VERSION ""

NS_ :

BS_:

BU_: Host Bootloader Application

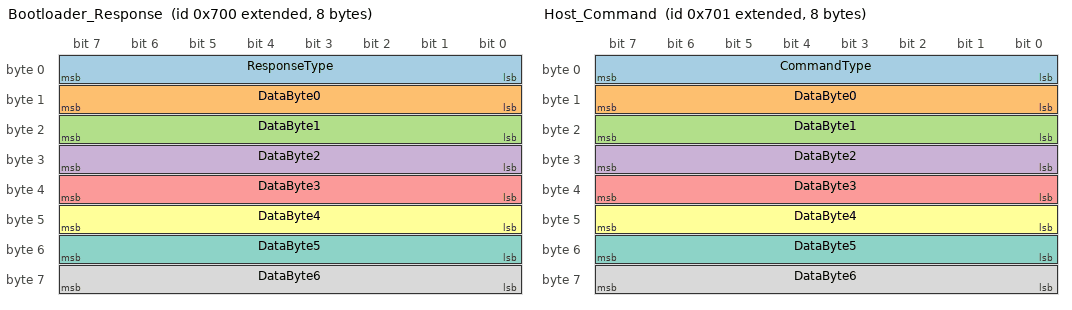
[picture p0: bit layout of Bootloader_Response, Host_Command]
BO_ 2684356352 Bootloader_Response: 8 Bootloader
 SG_ ResponseType : 0|8@1+ (1,0) [0|255] ""  Host
 SG_ DataByte0 : 8|8@1+ (1,0) [0|255] ""  Host
 SG_ DataByte1 : 16|8@1+ (1,0) [0|255] ""  Host
 SG_ DataByte2 : 24|8@1+ (1,0) [0|255] ""  Host
 SG_ DataByte3 : 32|8@1+ (1,0) [0|255] ""  Host
 SG_ DataByte4 : 40|8@1+ (1,0) [0|255] ""  Host
 SG_ DataByte5 : 48|8@1+ (1,0) [0|255] ""  Host
 SG_ DataByte6 : 56|8@1+ (1,0) [0|255] ""  Host

CM_ BO_ 2684356352 "Bootloader response messages to host PC. Contains ACK/NACK, status, data, and error information.";
CM_ SG_ 2684356352 ResponseType "Type of response: ACK(0x10), NACK(0x11), ERROR(0x12), BUSY(0x13), READY(0x14), DATA(0x15), JUMP_INFO(0x16)";
CM_ SG_ 2684356352 DataByte0 "Generic data byte 0 - ErrorCode for NACK/ERROR, Version for READY, Data for READ responses";
CM_ SG_ 2684356352 DataByte1 "Generic data byte 1 - State for STATUS, Data for READ responses";
CM_ SG_ 2684356352 DataByte2 "Generic data byte 2 - BytesWritten[0] for STATUS, Data for READ responses";
CM_ SG_ 2684356352 DataByte3 "Generic data byte 3 - BytesWritten[1] for STATUS, Data for READ responses";
CM_ SG_ 2684356352 DataByte4 "Generic data byte 4 - BytesWritten[2] for STATUS, Data for READ responses";
CM_ SG_ 2684356352 DataByte5 "Generic data byte 5 - BytesWritten[3] for STATUS, Data for READ responses";
CM_ SG_ 2684356352 DataByte6 "Generic data byte 6 - Data for READ responses";

VAL_ 2684356352 ResponseType 16 "ACK" 17 "NACK" 18 "ERROR" 19 "BUSY" 20 "READY" 21 "DATA" 22 "JUMP_INFO" ;
VAL_ 2684356352 DataByte0 0 "ERR_NONE" 1 "ERR_INVALID_COMMAND" 2 "ERR_INVALID_ADDRESS" 3 "ERR_FLASH_ERASE_FAILED" 4 "ERR_FLASH_WRITE_FAILED" 5 "ERR_INVALID_DATA_LENGTH" 6 "ERR_NO_VALID_APP" 7 "ERR_TIMEOUT" ;

BO_ 2684356353 Host_Command: 8 Host
 SG_ CommandType : 0|8@1+ (1,0) [0|255] ""  Bootloader
 SG_ DataByte0 : 8|8@1+ (1,0) [0|255] ""  Bootloader
 SG_ DataByte1 : 16|8@1+ (1,0) [0|255] ""  Bootloader
 SG_ DataByte2 : 24|8@1+ (1,0) [0|255] ""  Bootloader
 SG_ DataByte3 : 32|8@1+ (1,0) [0|255] ""  Bootloader
 SG_ DataByte4 : 40|8@1+ (1,0) [0|255] ""  Bootloader
 SG_ DataByte5 : 48|8@1+ (1,0) [0|255] ""  Bootloader
 SG_ DataByte6 : 56|8@1+ (1,0) [0|255] ""  Bootloader

CM_ BO_ 2684356353 "Host command messages to bootloader for firmware update operations";
CM_ SG_ 2684356353 CommandType "Command from host: ERASE(1), WRITE_FLASH(2), READ_FLASH(3), JUMP(4), STATUS(5), SET_ADDR(6), WRITE_DATA(7)";
CM_ SG_ 2684356353 DataByte0 "Data byte 0 - Address[31:24] for SET_ADDRESS, Data for WRITE_DATA, Length for READ_FLASH";
CM_ SG_ 2684356353 DataByte1 "Data byte 1 - Address[23:16] for SET_ADDRESS, Data for WRITE_DATA";
CM_ SG_ 2684356353 DataByte2 "Data byte 2 - Address[15:8] for SET_ADDRESS, Data for WRITE_DATA";
CM_ SG_ 2684356353 DataByte3 "Data byte 3 - Address[7:0] for SET_ADDRESS, Data for WRITE_DATA";
CM_ SG_ 2684356353 DataByte4 "Data byte 4 - DataLength for WRITE_DATA (always 0x04)";
CM_ SG_ 2684356353 DataByte5 "Data byte 5 - Reserved";
CM_ SG_ 2684356353 DataByte6 "Data byte 6 - Reserved";

VAL_ 2684356353 CommandType 1 "CMD_ERASE_FLASH" 2 "CMD_WRITE_FLASH" 3 "CMD_READ_FLASH" 4 "CMD_JUMP_TO_APP" 5 "CMD_GET_STATUS" 6 "CMD_SET_ADDRESS" 7 "CMD_WRITE_DATA" ;

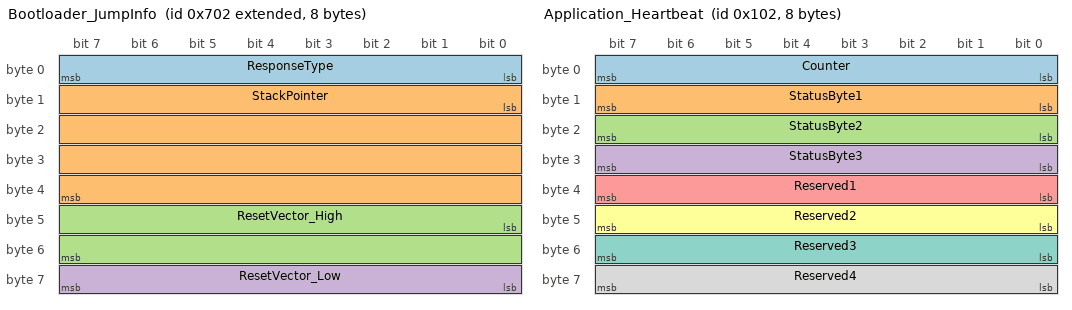
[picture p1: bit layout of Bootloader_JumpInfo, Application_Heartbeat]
BO_ 2684356354 Bootloader_JumpInfo: 8 Bootloader
 SG_ ResponseType : 0|8@1+ (1,0) [0|255] ""  Host
 SG_ StackPointer : 8|32@1+ (1,0) [0|4294967295] ""  Host
 SG_ ResetVector_High : 40|16@1+ (1,0) [0|65535] ""  Host
 SG_ ResetVector_Low : 56|8@1+ (1,0) [0|255] ""  Host

CM_ BO_ 2684356354 "Detailed jump to application diagnostics (sent immediately before jumping to application code)";
CM_ SG_ 2684356354 ResponseType "Always RESP_JUMP_INFO (0x16) for this message";
CM_ SG_ 2684356354 StackPointer "Application initial stack pointer from vector table at 0x08008000. Should be 0x2000xxxx (valid RAM address)";
CM_ SG_ 2684356354 ResetVector_High "Application reset handler address bits [23:8]. Combined with ResetVector_Low gives full address";
CM_ SG_ 2684356354 ResetVector_Low "Application reset handler address bits [7:0]. LSB should be 1 (Thumb mode). Full address should be 0x0800xxxx";

BO_ 258 Application_Heartbeat: 8 Application
 SG_ Counter : 0|8@1+ (1,0) [0|255] ""  Host,Bootloader
 SG_ StatusByte1 : 8|8@1+ (1,0) [0|255] ""  Host,Bootloader
 SG_ StatusByte2 : 16|8@1+ (1,0) [0|255] ""  Host,Bootloader
 SG_ StatusByte3 : 24|8@1+ (1,0) [0|255] ""  Host,Bootloader
 SG_ Reserved1 : 32|8@1+ (1,0) [0|255] ""  Host,Bootloader
 SG_ Reserved2 : 40|8@1+ (1,0) [0|255] ""  Host,Bootloader
 SG_ Reserved3 : 48|8@1+ (1,0) [0|255] ""  Host,Bootloader
 SG_ Reserved4 : 56|8@1+ (1,0) [0|255] ""  Host,Bootloader

CM_ BO_ 258 "Application heartbeat message sent every 10 seconds when application is running. Indicates successful jump from bootloader.";
CM_ SG_ 258 Counter "Heartbeat counter, increments with each message (rolls over at 255)";
CM_ SG_ 258 StatusByte1 "Status byte 1: Always 0x55 (signature)";
CM_ SG_ 258 StatusByte2 "Status byte 2: Always 0x01 (message type)";
CM_ SG_ 258 StatusByte3 "Status byte 3: Reserved";
CM_ SG_ 258 Reserved1 "Reserved for future use (application state, error flags, etc.)";
CM_ SG_ 258 Reserved2 "Reserved for future use";
CM_ SG_ 258 Reserved3 "Reserved for future use";
CM_ SG_ 258 Reserved4 "Reserved for future use";

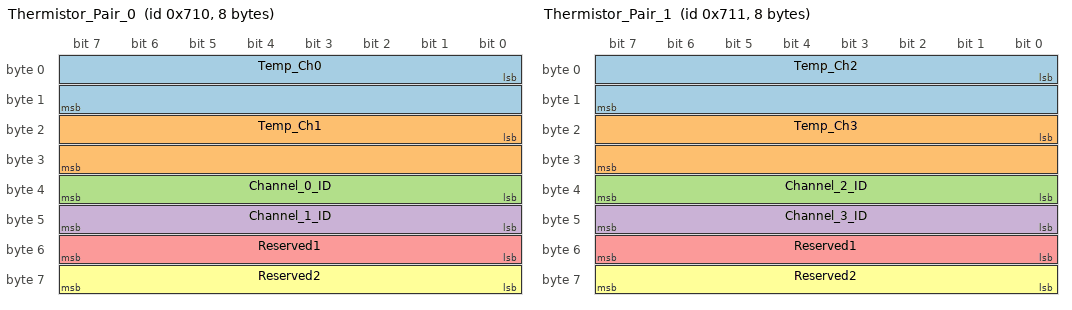
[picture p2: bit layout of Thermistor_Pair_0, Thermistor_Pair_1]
BO_ 1808 Thermistor_Pair_0: 8 Application
 SG_ Temp_Ch0 : 0|16@1- (0.1,0) [-400|1250] "degC"  Host
 SG_ Temp_Ch1 : 16|16@1- (0.1,0) [-400|1250] "degC"  Host
 SG_ Channel_0_ID : 32|8@1+ (1,0) [0|7] ""  Host
 SG_ Channel_1_ID : 40|8@1+ (1,0) [0|7] ""  Host
 SG_ Reserved1 : 48|8@1+ (1,0) [0|255] ""  Host
 SG_ Reserved2 : 56|8@1+ (1,0) [0|255] ""  Host

CM_ BO_ 1808 "Thermistor pair 0: Channels 0 and 1 temperature readings (sent every 2 seconds, 0.1°C resolution)";
CM_ SG_ 1808 Temp_Ch0 "Temperature from thermistor channel 0 (0.1°C resolution, little-endian signed 16-bit)";
CM_ SG_ 1808 Temp_Ch1 "Temperature from thermistor channel 1 (0.1°C resolution, little-endian signed 16-bit)";
CM_ SG_ 1808 Channel_0_ID "Always 0 - identifies first thermistor channel in this message";
CM_ SG_ 1808 Channel_1_ID "Always 1 - identifies second thermistor channel in this message";
CM_ SG_ 1808 Reserved1 "Reserved for future use";
CM_ SG_ 1808 Reserved2 "Reserved for future use";

BO_ 1809 Thermistor_Pair_1: 8 Application
 SG_ Temp_Ch2 : 0|16@1- (0.1,0) [-400|1250] "degC"  Host
 SG_ Temp_Ch3 : 16|16@1- (0.1,0) [-400|1250] "degC"  Host
 SG_ Channel_2_ID : 32|8@1+ (1,0) [0|7] ""  Host
 SG_ Channel_3_ID : 40|8@1+ (1,0) [0|7] ""  Host
 SG_ Reserved1 : 48|8@1+ (1,0) [0|255] ""  Host
 SG_ Reserved2 : 56|8@1+ (1,0) [0|255] ""  Host

CM_ BO_ 1809 "Thermistor pair 1: Channels 2 and 3 temperature readings (sent every 2 seconds, 0.1°C resolution)";
CM_ SG_ 1809 Temp_Ch2 "Temperature from thermistor channel 2 (0.1°C resolution, little-endian signed 16-bit)";
CM_ SG_ 1809 Temp_Ch3 "Temperature from thermistor channel 3 (0.1°C resolution, little-endian signed 16-bit)";
CM_ SG_ 1809 Channel_2_ID "Always 2 - identifies first thermistor channel in this message";
CM_ SG_ 1809 Channel_3_ID "Always 3 - identifies second thermistor channel in this message";
CM_ SG_ 1809 Reserved1 "Reserved for future use";
CM_ SG_ 1809 Reserved2 "Reserved for future use";

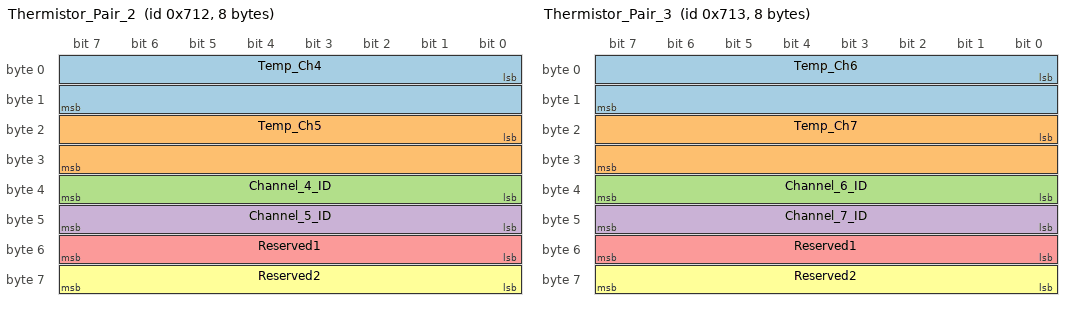
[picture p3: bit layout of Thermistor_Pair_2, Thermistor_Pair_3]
BO_ 1810 Thermistor_Pair_2: 8 Application
 SG_ Temp_Ch4 : 0|16@1- (0.1,0) [-400|1250] "degC"  Host
 SG_ Temp_Ch5 : 16|16@1- (0.1,0) [-400|1250] "degC"  Host
 SG_ Channel_4_ID : 32|8@1+ (1,0) [0|7] ""  Host
 SG_ Channel_5_ID : 40|8@1+ (1,0) [0|7] ""  Host
 SG_ Reserved1 : 48|8@1+ (1,0) [0|255] ""  Host
 SG_ Reserved2 : 56|8@1+ (1,0) [0|255] ""  Host

CM_ BO_ 1810 "Thermistor pair 2: Channels 4 and 5 temperature readings (sent every 2 seconds, 0.1°C resolution)";
CM_ SG_ 1810 Temp_Ch4 "Temperature from thermistor channel 4 (0.1°C resolution, little-endian signed 16-bit)";
CM_ SG_ 1810 Temp_Ch5 "Temperature from thermistor channel 5 (0.1°C resolution, little-endian signed 16-bit)";
CM_ SG_ 1810 Channel_4_ID "Always 4 - identifies first thermistor channel in this message";
CM_ SG_ 1810 Channel_5_ID "Always 5 - identifies second thermistor channel in this message";
CM_ SG_ 1810 Reserved1 "Reserved for future use";
CM_ SG_ 1810 Reserved2 "Reserved for future use";

BO_ 1811 Thermistor_Pair_3: 8 Application
 SG_ Temp_Ch6 : 0|16@1- (0.1,0) [-400|1250] "degC"  Host
 SG_ Temp_Ch7 : 16|16@1- (0.1,0) [-400|1250] "degC"  Host
 SG_ Channel_6_ID : 32|8@1+ (1,0) [0|7] ""  Host
 SG_ Channel_7_ID : 40|8@1+ (1,0) [0|7] ""  Host
 SG_ Reserved1 : 48|8@1+ (1,0) [0|255] ""  Host
 SG_ Reserved2 : 56|8@1+ (1,0) [0|255] ""  Host

CM_ BO_ 1811 "Thermistor pair 3: Channels 6 and 7 temperature readings (sent every 2 seconds, 0.1°C resolution)";
CM_ SG_ 1811 Temp_Ch6 "Temperature from thermistor channel 6 (0.1°C resolution, little-endian signed 16-bit)";
CM_ SG_ 1811 Temp_Ch7 "Temperature from thermistor channel 7 (0.1°C resolution, little-endian signed 16-bit)";
CM_ SG_ 1811 Channel_6_ID "Always 6 - identifies first thermistor channel in this message";
CM_ SG_ 1811 Channel_7_ID "Always 7 - identifies second thermistor channel in this message";
CM_ SG_ 1811 Reserved1 "Reserved for future use";
CM_ SG_ 1811 Reserved2 "Reserved for future use";

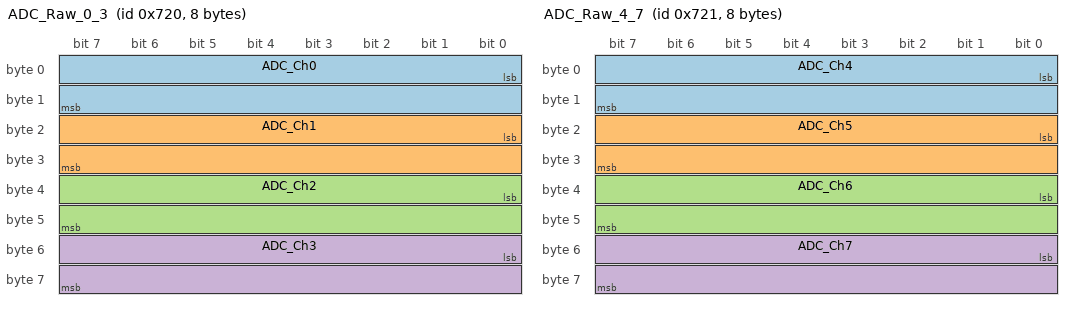
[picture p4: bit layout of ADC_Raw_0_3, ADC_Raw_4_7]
BO_ 1824 ADC_Raw_0_3: 8 Application
 SG_ ADC_Ch0 : 0|16@1+ (1,0) [0|4095] "counts"  Host
 SG_ ADC_Ch1 : 16|16@1+ (1,0) [0|4095] "counts"  Host
 SG_ ADC_Ch2 : 32|16@1+ (1,0) [0|4095] "counts"  Host
 SG_ ADC_Ch3 : 48|16@1+ (1,0) [0|4095] "counts"  Host

CM_ BO_ 1824 "Raw ADC values for thermistor channels 0-3 (diagnostic message, sent every 2 seconds)";
CM_ SG_ 1824 ADC_Ch0 "Raw 12-bit ADC reading from thermistor channel 0 (0-4095 counts)";
CM_ SG_ 1824 ADC_Ch1 "Raw 12-bit ADC reading from thermistor channel 1 (0-4095 counts)";
CM_ SG_ 1824 ADC_Ch2 "Raw 12-bit ADC reading from thermistor channel 2 (0-4095 counts)";
CM_ SG_ 1824 ADC_Ch3 "Raw 12-bit ADC reading from thermistor channel 3 (0-4095 counts)";

BO_ 1825 ADC_Raw_4_7: 8 Application
 SG_ ADC_Ch4 : 0|16@1+ (1,0) [0|4095] "counts"  Host
 SG_ ADC_Ch5 : 16|16@1+ (1,0) [0|4095] "counts"  Host
 SG_ ADC_Ch6 : 32|16@1+ (1,0) [0|4095] "counts"  Host
 SG_ ADC_Ch7 : 48|16@1+ (1,0) [0|4095] "counts"  Host

CM_ BO_ 1825 "Raw ADC values for thermistor channels 4-7 (diagnostic message, sent every 2 seconds)";
CM_ SG_ 1825 ADC_Ch4 "Raw 12-bit ADC reading from thermistor channel 4 (0-4095 counts)";
CM_ SG_ 1825 ADC_Ch5 "Raw 12-bit ADC reading from thermistor channel 5 (0-4095 counts)";
CM_ SG_ 1825 ADC_Ch6 "Raw 12-bit ADC reading from thermistor channel 6 (0-4095 counts)";
CM_ SG_ 1825 ADC_Ch7 "Raw 12-bit ADC reading from thermistor channel 7 (0-4095 counts)";

BA_DEF_ "BusType" STRING ;
BA_DEF_ BO_ "GenMsgCycleTime" INT 0 10000;
BA_DEF_ BO_ "GenMsgSendType" STRING ;

BA_DEF_DEF_ "BusType" "CAN";
BA_DEF_DEF_ "GenMsgCycleTime" 0;
BA_DEF_DEF_ "GenMsgSendType" "cyclic";

BA_ "GenMsgCycleTime" BO_ 258 10000;
BA_ "GenMsgCycleTime" BO_ 1808 1000;
BA_ "GenMsgCycleTime" BO_ 1809 1000;
BA_ "GenMsgCycleTime" BO_ 1810 1000;
BA_ "GenMsgCycleTime" BO_ 1811 1000;
BA_ "GenMsgCycleTime" BO_ 1824 2000;
BA_ "GenMsgCycleTime" BO_ 1825 2000;
BA_ "GenMsgSendType" BO_ 2684356352 "event";
BA_ "GenMsgSendType" BO_ 2684356353 "event";
BA_ "GenMsgSendType" BO_ 2684356354 "event";
